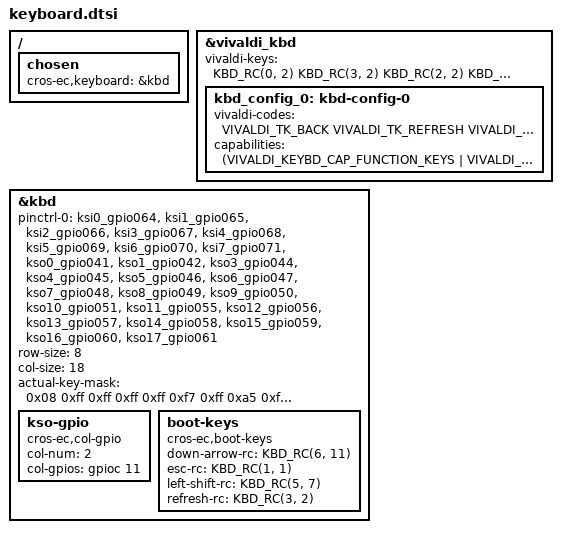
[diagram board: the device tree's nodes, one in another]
/* Copyright 2025 The ChromiumOS Authors
 * Use of this source code is governed by a BSD-style license that can be
 * found in the LICENSE file.
 */

/ {
	chosen {
		cros-ec,keyboard = &kbd;
	};
};

&vivaldi_kbd {
	vivaldi-keys = <
		KBD_RC(0, 2)   /* T1 */
		KBD_RC(3, 2)   /* T2 */
		KBD_RC(2, 2)   /* T3 */
		KBD_RC(1, 2)   /* T4 */
		KBD_RC(4, 4)   /* T5 */
		KBD_RC(2, 4)   /* T6 */
		KBD_RC(1, 4)   /* T7 */
		KBD_RC(2, 11)  /* T8 */
		KBD_RC(1, 9)   /* T9 */
		KBD_RC(0, 4)   /* T10 */
		KBD_RC(0, 1)   /* T11 */
		KBD_RC(1, 5)   /* T12 */
		KBD_RC(3, 5)   /* T13 */
		KBD_RC(0, 11)  /* T14 */
	>;

	kbd_config_0: kbd-config-0 {
		vivaldi-codes = <
			VIVALDI_TK_BACK               /* T1 */
			VIVALDI_TK_REFRESH            /* T2 */
			VIVALDI_TK_FULLSCREEN         /* T3 */
			VIVALDI_TK_OVERVIEW           /* T4 */
			VIVALDI_TK_SNAPSHOT           /* T5 */
			VIVALDI_TK_BRIGHTNESS_DOWN    /* T6 */
			VIVALDI_TK_BRIGHTNESS_UP      /* T7 */
			VIVALDI_TK_DICTATE 			  /* T8 */
			VIVALDI_TK_ACCESSIBILITY      /* T9 */
			VIVALDI_TK_PLAY_PAUSE         /* T10 */
			VIVALDI_TK_VOL_MUTE           /* T11 */
			VIVALDI_TK_VOL_DOWN           /* T12 */
			VIVALDI_TK_VOL_UP             /* T13 */
		>;
		capabilities = <(VIVALDI_KEYBD_CAP_FUNCTION_KEYS |
				VIVALDI_KEYBD_CAP_NUMERIC_KEYPAD |
				VIVALDI_KEYBD_CAP_SCRNLOCK_KEY |
				VIVALDI_KEYBD_CAP_ASSISTANT_KEY)>;
	};
};

&kbd {
	status = "okay";
	pinctrl-0 = <
		&ksi0_gpio064
		&ksi1_gpio065
		&ksi2_gpio066
		&ksi3_gpio067
		&ksi4_gpio068
		&ksi5_gpio069
		&ksi6_gpio070
		&ksi7_gpio071
		&kso0_gpio041
		&kso1_gpio042
		&kso3_gpio044
		&kso4_gpio045
		&kso5_gpio046
		&kso6_gpio047
		&kso7_gpio048
		&kso8_gpio049
		&kso9_gpio050
		&kso10_gpio051
		&kso11_gpio055
		&kso12_gpio056
		&kso13_gpio057
		&kso14_gpio058
		&kso15_gpio059
		&kso16_gpio060
		&kso17_gpio061
	>;
	row-size = <8>;
	col-size = <18>;
	pinctrl-names = "default";

	actual-key-mask = <
		0x08  /* C0 */
		0xff  /* C1 */
		0xff  /* C2 */
		0xff  /* C3 */
		0xff  /* C4 */
		0xf7  /* C5 */
		0xff  /* C6 */
		0xa5  /* C7 */
		0xff  /* C8 */
		0xff  /* C9 */
		0x01  /* C10 */
		0xfe  /* C11 */
		0xfe  /* C12 */
		0x40  /* C13 */
		0x0a  /* C14 */
		0x40  /* C15 */
		0x01  /* C16 */
		0xd4  /* C17 */
	>;

	kso-gpio {
		compatible = "cros-ec,col-gpio";
		col-num = <2>;
		col-gpios = <&gpioc 11 GPIO_ACTIVE_HIGH>;
	};

	boot-keys {
		compatible = "cros-ec,boot-keys";
		down-arrow-rc = <KBD_RC(6, 11)>;
		esc-rc = <KBD_RC(1, 1)>;
		left-shift-rc = <KBD_RC(5, 7)>;
		refresh-rc = <KBD_RC(3, 2)>;
	};
};
